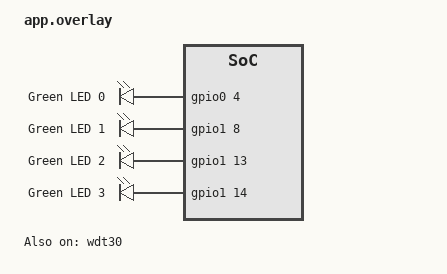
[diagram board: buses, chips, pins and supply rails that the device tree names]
/*
 * Copyright (c) 2024 Nordic Semiconductor ASA
 *
 * SPDX-License-Identifier: LicenseRef-Nordic-5-Clause
 */

/* Redefine the partition map. */
&rram0 {
	/delete-node/ partitions;

	partitions {
		compatible = "fixed-partitions";
		#address-cells = <1>;
		#size-cells = <1>;
		app_partition: partition@0 {
			label = "application";
			reg = <0x0 0x177000>;
		};

		storage_partition: partition@177000 {
			label = "storage";
			reg = <0x177000 0x6000>;
		};
	};
};

/* For nRF54L, watchdog status is disabled by default. Needs to be enabled in DTS overlay. */
&wdt30 {
	status = "okay";
};

/ {
	chosen {
		zephyr,flash = &rram0;
		zephyr,code-partition = &app_partition;
	};

	/* Disable leds and redefine them to align configuration with CAF LEDs requirements. */
	leds {
		status = "disabled";
	};

	gpioled0 {
		compatible = "gpio-leds";
		status = "okay";
		label = "LED System State";

		led0_g: led_0 {
			gpios = <&gpio0 4 GPIO_ACTIVE_HIGH>;
			label = "Green LED 0";
		};
	};

	gpioled1 {
		compatible = "gpio-leds";
		status = "okay";
		label = "LED Conn State";

		led1_g: led_1 {
			gpios = <&gpio1 8 GPIO_ACTIVE_HIGH>;
			label = "Green LED 1";
		};
	};

	gpioled2 {
		compatible = "gpio-leds";
		status = "okay";
		label = "LED Num Lock";

		led2_g: led_2 {
			gpios = <&gpio1 13 GPIO_ACTIVE_HIGH>;
			label = "Green LED 2";
		};
	};

	gpioled3 {
		compatible = "gpio-leds";
		status = "okay";
		label = "LED Caps Lock";

		led3_g: led_3 {
			gpios = <&gpio1 14 GPIO_ACTIVE_HIGH>;
			label = "Green LED 3";
		};
	};
};
